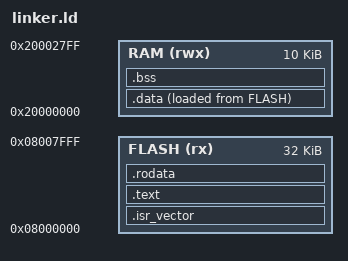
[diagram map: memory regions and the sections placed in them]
/* ============================================================
 * STM32F103C6T6 Linker Script
 * ============================================================ */

ENTRY(Reset_Handler)


/* ============================================================
 * Memory layout
 * ============================================================ */

MEMORY
{
    FLASH (rx)  : ORIGIN = 0x08000000, LENGTH = 32K
    RAM   (rwx) : ORIGIN = 0x20000000, LENGTH = 10K
}


/* ============================================================
 * Sections
 * ============================================================ */

SECTIONS
{
    /*
     * --------------------------------------------------------
     * Interrupt vector table
     * --------------------------------------------------------
     */

    .isr_vector :
    {
        . = ALIGN(4);

        KEEP(*(.isr_vector))

        . = ALIGN(4);
    } > FLASH


    /*
     * --------------------------------------------------------
     * Program code
     * --------------------------------------------------------
     */

    .text :
    {
        . = ALIGN(4);

        *(.text)
        *(.text.*)

        . = ALIGN(4);

    } > FLASH


    /*
     * --------------------------------------------------------
     * Read-only data
     * --------------------------------------------------------
     */

    .rodata :
    {
        . = ALIGN(4);

        *(.rodata)
        *(.rodata.*)

        . = ALIGN(4);

    } > FLASH


    /*
     * --------------------------------------------------------
     * Initialized data
     *
     * Initial values are stored in Flash,
     * but copied to RAM during Reset_Handler.
     * --------------------------------------------------------
     */

    .data :
    {
        . = ALIGN(4);

        _sdata = .;

        *(.data)
        *(.data.*)

        . = ALIGN(4);

        _edata = .;

    } > RAM AT > FLASH


    /*
     * Address in Flash where .data initial values are stored.
     */

    _sidata = LOADADDR(.data);


    /*
     * --------------------------------------------------------
     * Uninitialized data
     * --------------------------------------------------------
     */

    .bss :
    {
        . = ALIGN(4);

        _sbss = .;

        *(.bss)
        *(.bss.*)
        *(COMMON)

        . = ALIGN(4);

        _ebss = .;

    } > RAM


    /*
     * --------------------------------------------------------
     * End of RAM
     * --------------------------------------------------------
     */

    . = ALIGN(8);

    _end = .;


    /*
     * --------------------------------------------------------
     * Stack
     *
     * Stack starts at the top of RAM and grows downward.
     * --------------------------------------------------------
     */

    _estack = ORIGIN(RAM) + LENGTH(RAM);


    /*
     * --------------------------------------------------------
     * Remove unnecessary sections
     * --------------------------------------------------------
     */

    /DISCARD/ :
    {
        *(.note.GNU-stack)
        *(.comment)
    }
}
